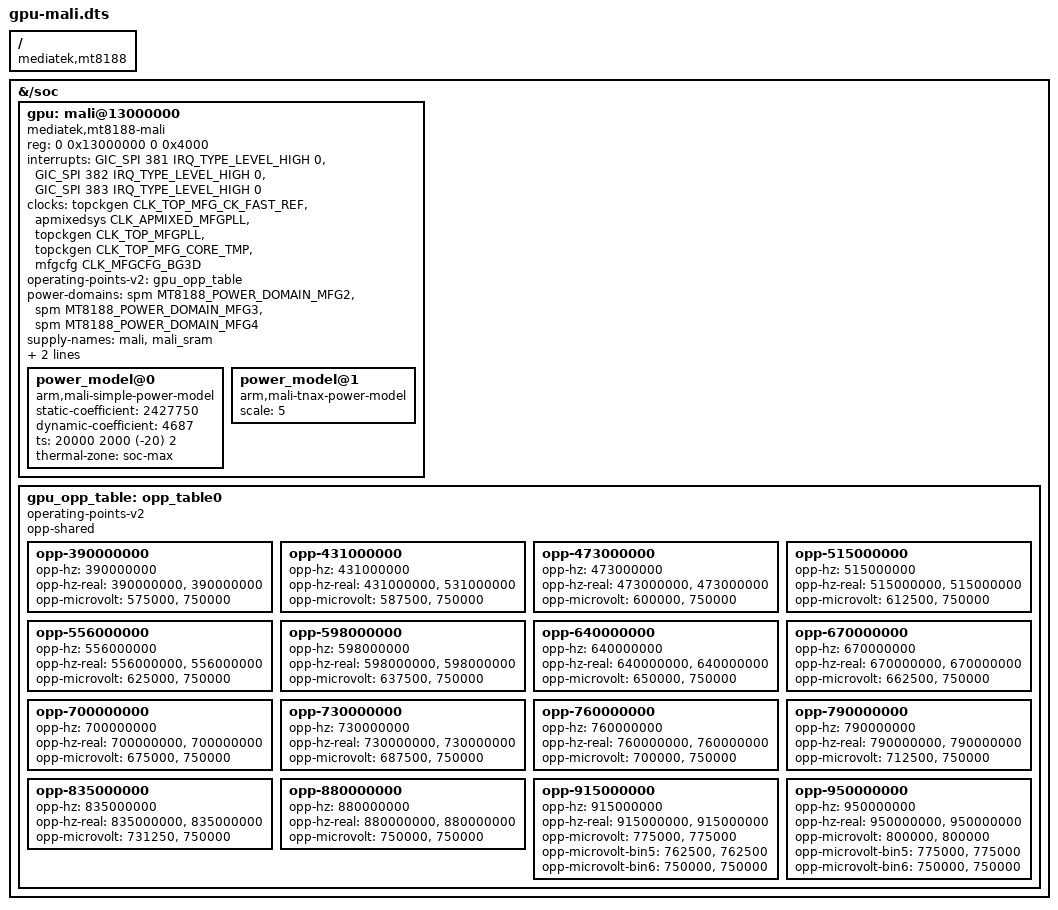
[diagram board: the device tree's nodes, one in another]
// SPDX-License-Identifier: (GPL-2.0 OR MIT)
/*
 * Copyright (c) 2021 MediaTek Inc.
 * Author: kidd-kw.chen <kidd-kw.chen@mediatek.com>
 */

/dts-v1/;
/plugin/;
#include <dt-bindings/clock/mediatek,mt8188-clk.h>
#include <dt-bindings/power/mediatek,mt8188-power.h>
#include <dt-bindings/interrupt-controller/arm-gic.h>
#include <dt-bindings/interrupt-controller/irq.h>
#include <dt-bindings/memory/mediatek,mt8188-memory-port.h>

/ {
	compatible = "mediatek,mt8188";

	fragment@0 {
		target-path = "/soc";
		__overlay__ {
			gpu: mali@13000000 {
				compatible = "mediatek,mt8188-mali", "arm,mali-midgard";
				reg = <0 0x13000000 0 0x4000>;
				interrupts =
					<GIC_SPI 381 IRQ_TYPE_LEVEL_HIGH 0>,
					<GIC_SPI 382 IRQ_TYPE_LEVEL_HIGH 0>,
					<GIC_SPI 383 IRQ_TYPE_LEVEL_HIGH 0>;
				interrupt-names =
					"GPU",
					"MMU",
					"JOB";

				/*
				 * Note: the properties below are not part of the
				 * upstream binding.
				 */
				clocks =
					<&topckgen CLK_TOP_MFG_CK_FAST_REF>,
					<&apmixedsys CLK_APMIXED_MFGPLL>,
					<&topckgen CLK_TOP_MFGPLL>,
					<&topckgen CLK_TOP_MFG_CORE_TMP>,
					<&mfgcfg CLK_MFGCFG_BG3D>;

				clock-names =
					"clk_mux",
					"clk_pll_src",
					"clk_main_parent",
					"clk_sub_parent",
					"subsys_bg3d";

				operating-points-v2 = <&gpu_opp_table>;

				power-domains =
					<&spm MT8188_POWER_DOMAIN_MFG2>,
					<&spm MT8188_POWER_DOMAIN_MFG3>,
					<&spm MT8188_POWER_DOMAIN_MFG4>;
				power-domain-names =
					"core0",
					"core1",
					"core2";

				supply-names = "mali","mali_sram";
				mali-supply = <&mt6359_vproc2_buck_reg>;
				mali_sram-supply = <&mt6359_vsram_others_ldo_reg>;

				status = "okay";

				power_model@0 {
					compatible = "arm,mali-simple-power-model";
					static-coefficient = <2427750>;
					dynamic-coefficient = <4687>;
					ts = <20000 2000 (-20) 2>;
					thermal-zone = "soc-max";
				};
				power_model@1 {
					compatible = "arm,mali-tnax-power-model";
					scale = <5>;
				};
			};

			gpu_opp_table: opp_table0 {
				/*
				 * Note: "operating-points-v2-mali" compatible and the
				 * opp-core-mask properties are not part of upstream
				 * binding.
				 */

				compatible = "operating-points-v2", "operating-points-v2-mali";
				opp-shared;

				opp-390000000 {
					opp-hz = /bits/ 64 <390000000>;
					opp-hz-real = /bits/ 64 <390000000>,
							  /bits/ 64 <390000000>;
					opp-microvolt = <575000>, <750000>;
				};

				opp-431000000 {
					opp-hz = /bits/ 64 <431000000>;
					opp-hz-real = /bits/ 64 <431000000>,
							  /bits/ 64 <531000000>;
					opp-microvolt = <587500>, <750000>;
				};

				opp-473000000 {
					opp-hz = /bits/ 64 <473000000>;
					opp-hz-real = /bits/ 64 <473000000>,
							  /bits/ 64 <473000000>;
					opp-microvolt = <600000>, <750000>;
				};

				opp-515000000 {
					opp-hz = /bits/ 64 <515000000>;
					opp-hz-real = /bits/ 64 <515000000>,
							  /bits/ 64 <515000000>;
					opp-microvolt = <612500>, <750000>;
				};

				opp-556000000 {
					opp-hz = /bits/ 64 <556000000>;
					opp-hz-real = /bits/ 64 <556000000>,
							  /bits/ 64 <556000000>;
					opp-microvolt = <625000>, <750000>;
				};

				opp-598000000 {
					opp-hz = /bits/ 64 <598000000>;
					opp-hz-real = /bits/ 64 <598000000>,
							  /bits/ 64 <598000000>;
					opp-microvolt = <637500>, <750000>;
				};

				opp-640000000 {
					opp-hz = /bits/ 64 <640000000>;
					opp-hz-real = /bits/ 64 <640000000>,
							  /bits/ 64 <640000000>;
					opp-microvolt = <650000>, <750000>;
				};

				opp-670000000 {
					opp-hz = /bits/ 64 <670000000>;
					opp-hz-real = /bits/ 64 <670000000>,
							  /bits/ 64 <670000000>;
					opp-microvolt = <662500>, <750000>;
				};

				opp-700000000 {
					opp-hz = /bits/ 64 <700000000>;
					opp-hz-real = /bits/ 64 <700000000>,
							  /bits/ 64 <700000000>;
					opp-microvolt = <675000>, <750000>;
				};

				opp-730000000 {
					opp-hz = /bits/ 64 <730000000>;
					opp-hz-real = /bits/ 64 <730000000>,
							  /bits/ 64 <730000000>;
					opp-microvolt = <687500>, <750000>;
				};

				opp-760000000 {
					opp-hz = /bits/ 64 <760000000>;
					opp-hz-real = /bits/ 64 <760000000>,
							  /bits/ 64 <760000000>;
					opp-microvolt = <700000>, <750000>;
				};

				opp-790000000 {
					opp-hz = /bits/ 64 <790000000>;
					opp-hz-real = /bits/ 64 <790000000>,
							  /bits/ 64 <790000000>;
					opp-microvolt = <712500>, <750000>;
				};

				opp-835000000 {
					opp-hz = /bits/ 64 <835000000>;
					opp-hz-real = /bits/ 64 <835000000>,
							  /bits/ 64 <835000000>;
					opp-microvolt = <731250>, <750000>;
				};

				opp-880000000 {
					opp-hz = /bits/ 64 <880000000>;
					opp-hz-real = /bits/ 64 <880000000>,
							  /bits/ 64 <880000000>;
					opp-microvolt = <750000>, <750000>;
				};

				opp-915000000 {
					opp-hz = /bits/ 64 <915000000>;
					opp-hz-real = /bits/ 64 <915000000>,
							  /bits/ 64 <915000000>;
					opp-microvolt = <775000>, <775000>;
					opp-microvolt-bin5 = <762500>, <762500>;
					opp-microvolt-bin6 = <750000>, <750000>;
				};

				opp-950000000 {
					opp-hz = /bits/ 64 <950000000>;
					opp-hz-real = /bits/ 64 <950000000>,
							  /bits/ 64 <950000000>;
					opp-microvolt = <800000>, <800000>;
					opp-microvolt-bin5 = <775000>, <775000>;
					opp-microvolt-bin6 = <750000>, <750000>;
				};
			};
		};
	};
};
